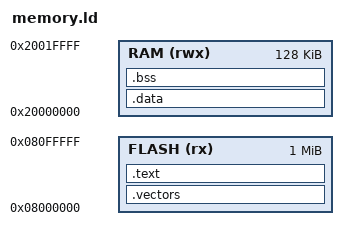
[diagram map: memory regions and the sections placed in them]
ENTRY(reset_handler)

MEMORY
{
    FLASH (rx)  : ORIGIN = 0x08000000, LENGTH = 1024K
    RAM   (rwx) : ORIGIN = 0x20000000, LENGTH = 128K
}

_stack_top = ORIGIN(RAM) + LENGTH(RAM);

SECTIONS
{
    .vectors :
    {
        KEEP(*(.vectors))
    } > FLASH

    .text :
    {
        *(.text*)
        *(.rodata*)
    } > FLASH

    .data :
    {
        *(.data*)
    } > RAM

    .bss (NOLOAD) :
    {
        *(.bss*)
        *(COMMON)
    } > RAM

    /DISCARD/ :
    {
        *(.comment)
        *(.ARM.attributes)
        *(.ARM.exidx*)
        *(.eh_frame*)
    }
}
